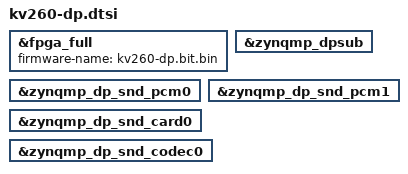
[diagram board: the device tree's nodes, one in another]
// SPDX-License-Identifier: GPL-2.0
/*
 * dts file for KV260 DP subsystem
 *
 * (C) Copyright 2021, Xilinx, Inc.
 *
 * Michal Simek <michal.simek@xilinx.com>
 */

/dts-v1/;
/plugin/;

&fpga_full {
	#address-cells = <2>;
	#size-cells = <2>;
	firmware-name = "kv260-dp.bit.bin";
};

&zynqmp_dpsub {
	status = "okay";
};

&zynqmp_dp_snd_pcm0 {
	status = "okay";
};

&zynqmp_dp_snd_pcm1 {
	status = "okay";
};

&zynqmp_dp_snd_card0 {
	status = "okay";
};

&zynqmp_dp_snd_codec0 {
	status = "okay";
};
